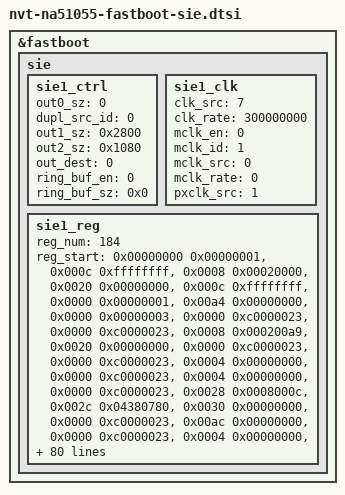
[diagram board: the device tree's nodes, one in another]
&fastboot {
	sie {
		sie1_ctrl {
			out0_sz = <0>;
			dupl_src_id = <0>;
			out1_sz = <0x2800>;
			out2_sz = <0x1080>;
			out_dest = <0>;
			ring_buf_en = <0>;
			ring_buf_sz = <0x0>;
		};

		sie1_clk {
			clk_src = <7>;
			clk_rate = <300000000>;
			mclk_en = <0>;
			mclk_id = <1>;
			mclk_src = <0>;
			mclk_rate = <0>;
			pxclk_src = <1>;
		};

		sie1_reg {
			reg_num = <184>;
			reg_start = <0x00000000 0x00000001>,
			<0x000c 0xffffffff>,
			<0x0008 0x00020000>,
			<0x0020 0x00000000>,
			<0x000c 0xffffffff>,
			<0x0000 0x00000001>,
			<0x00a4 0x00000000>,
			<0x0000 0x00000003>,
			<0x0000 0xc0000023>,
			<0x0000 0xc0000023>,
			<0x0008 0x000200a9>,
			<0x0020 0x00000000>,
			<0x0000 0xc0000023>,
			<0x0000 0xc0000023>,
			<0x0004 0x00000000>,
			<0x0000 0xc0000023>,
			<0x0004 0x00000000>,
			<0x0000 0xc0000023>,
			<0x0028 0x0008000c>,
			<0x002c 0x04380780>,
			<0x0030 0x00000000>,
			<0x0000 0xc0000023>,
			<0x00ac 0x00000000>,
			<0x0000 0xc0000023>,
			<0x0004 0x00000000>,
			<0x0000 0xc0000023>,
			<0x0000 0xc0000023>,
			<0x005c 0x00400000>,
			<0x0060 0x00020000>,
			<0x0064 0x00000000>,
			<0x0000 0xc0000023>,
			<0x0004 0x00000000>,
			<0x0000 0xc0000023>,
			<0x0028 0x0008000c>,
			<0x002c 0x04380780>,
			<0x0030 0x00000000>,
			<0x0000 0xc0000023>,
			<0x0030 0x00000000>,
			<0x0034 0x00000000>,
			<0x0038 0x04380780>,
			<0x0000 0xc0000023>,
			<0x0030 0x00000000>,
			<0x0034 0x00000000>,
			<0x0038 0x04380780>,
			<0x0000 0xc0000023>,
			<0x0000 0xc0000023>,
			<0x0000 0xc0000023>,
			<0x005c 0x00400000>,
			<0x0060 0x00020b40>,
			<0x0064 0x00000000>,
			<0x0000 0xc0000023>,
			<0x0024 0x0000006c>,
			<0x0000 0xc0000023>,
			<0x0008 0x000200a9>,
			<0x0020 0x00000000>,
			<0x0000 0xc0000023>,
			<0x0004 0x00000000>,
			<0x0000 0xc0000023>,
			<0x0004 0x00000000>,
			<0x0000 0xc0000023>,
			<0x00ac 0x00000000>,
			<0x0000 0xc0000023>,
			<0x0060 0x00020b40>,
			<0x006c 0x00000000>,
			<0x0000 0xc0000023>,
			<0x0000 0xc0000023>,
			<0x0004 0x00000000>,
			<0x0000 0xc0000023>,
			<0x0004 0x00000000>,
			<0x0000 0xc0000023>,
			<0x005c 0x00400000>,
			<0x0060 0x00020b40>,
			<0x0064 0x00000000>,
			<0x0000 0xc0000023>,
			<0x0004 0x00000000>,
			<0x0000 0xc0000023>,
			<0x0024 0x0000006c>,
			<0x0000 0xc0000023>,
			<0x0008 0x000200a9>,
			<0x0020 0x00000000>,
			<0x0000 0xc0000023>,
			<0x0004 0x00000000>,
			<0x0000 0xc0000023>,
			<0x0068 0x128020c0>,
			<0x006c 0x00000000>,
			<0x0070 0x00000000>,
			<0x0074 0x128048c0>,
			<0x0078 0x00000000>,
			<0x007c 0x00000000>,
			<0x0000 0xc0000023>,
			<0x00a4 0x70000000>,
			<0x0000 0xc0000023>,
			<0x0004 0x00000000>,
			<0x0000 0xc0000023>,
			<0x01b4 0x00800080>,
			<0x01b8 0x00800080>,
			<0x01bc 0x00010080>,
			<0x0000 0xc0000023>,
			<0x01e8 0x0000102c>,
			<0x0350 0x00000000>,
			<0x0000 0xc0000023>,
			<0x0220 0x00000000>,
			<0x0228 0x04380780>,
			<0x0030 0x00000000>,
			<0x0224 0x08740c06>,
			<0x023c 0x0000080a>,
			<0x0240 0x00001f1f>,
			<0x0248 0x00000000>,
			<0x024c 0x01000140>,
			<0x02ac 0x0000080a>,
			<0x02b0 0x00001f1f>,
			<0x0000 0xc0000023>,
			<0x0244 0x00000000>,
			<0x0000 0xc0000023>,
			<0x02a8 0x00100100>,
			<0x0000 0xc0000023>,
			<0x01ec 0x00800080>,
			<0x01f0 0x00000080>,
			<0x0000 0xc0000023>,
			<0x0250 0x08b12400>,
			<0x0254 0x1113c4c6>,
			<0x0258 0x16853530>,
			<0x025c 0x1b166d82>,
			<0x0260 0x1ed76dc7>,
			<0x0264 0x21b835fe>,
			<0x0268 0x2448da29>,
			<0x026c 0x26d97e52>,
			<0x0270 0x293a1e7a>,
			<0x0274 0x2b9ab2a0>,
			<0x0278 0x2ddb46c5>,
			<0x027c 0x2ffbd2e8>,
			<0x0280 0x31dc4f09>,
			<0x0284 0x33acc326>,
			<0x0288 0x356d3743>,
			<0x028c 0x372da35f>,
			<0x0290 0x38ce137b>,
			<0x0294 0x3a6e7b95>,
			<0x0298 0x3bfedfaf>,
			<0x029c 0x3d8f43c8>,
			<0x02a0 0x3effa3e0>,
			<0x02a4 0x000ffff7>,
			<0x0000 0xc0000023>,
			<0x01f4 0x00000000>,
			<0x0000 0xc0000023>,
			<0x02a8 0x00100100>,
			<0x0000 0xc0000023>,
			<0x00cc 0x00000000>,
			<0x0030 0x00000000>,
			<0x0000 0xc0000023>,
			<0x0048 0x11084918>,
			<0x0000 0xc0000023>,
			<0x0050 0x11088928>,
			<0x0000 0xc0000023>,
			<0x0154 0x00080010>,
			<0x0158 0x0f2f0889>,
			<0x0000 0xc0000023>,
			<0x015c 0x00000100>,
			<0x0000 0xc0000023>,
			<0x00bc 0x00000100>,
			<0x0000 0xc0000023>,
			<0x00b4 0x00000000>,
			<0x00b8 0x00000000>,
			<0x00bc 0x00000100>,
			<0x00c0 0x00000000>,
			<0x0000 0xc0000023>,
			<0x01e8 0x0000102c>,
			<0x0350 0x00000000>,
			<0x0000 0xc0000023>,
			<0x03c0 0x004e2030>,
			<0x03c4 0x0007a120>,
			<0x03c8 0x00064000>,
			<0x03d0 0x00000001>,
			<0x03d4 0xffffffff>,
			<0x03d8 0xffffffff>,
			<0x0000 0xc0000023>,
			<0x0004 0x01a19a20>,
			<0x0000 0xc0000023>,
			<0x0000 0xc0024023>,
			<0x0000 0xc0024023>,
			<0x00a8 0x00850000>,
			<0x000c 0xffffffff>,
			<0x0000 0xc0024022>,
			<0x0000 0xc0024026>,
			<0x0000 0xc0024026>;
		};

	};
};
